AUTOSAR XML (schema 00050)
standard types defined: Boolean
package /ARRoot
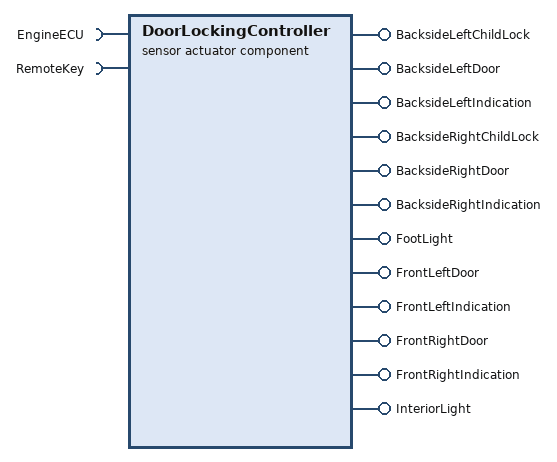
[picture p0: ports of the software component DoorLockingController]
  sensor actuator sw component type DoorLockingController
    6 x provide port:
      BacksideLeftChildLock
      BacksideLeftDoor
      BacksideLeftIndication
      BacksideRightChildLock
      BacksideRightDoor
      BacksideRightIndication
    require port EngineECU
    6 x provide port:
      FootLight
      FrontLeftDoor
      FrontLeftIndication
      FrontRightDoor
      FrontRightIndication
      InteriorLight
    require port RemoteKey
    swc-internal-behavior:
      15 x runnable:
        BacksideLeftChildLockRunnable
        BacksideLeftDoorRunnable
        BacksideLeftIndicationRunnable
        BacksideRightChildLockRunnable
        BacksideRightDoorRunnable
        BacksideRightDoorRunnable
        BacksideRightIndicationRunnable
        EngineECURunnable
        FootLightRunnable
        FrontLeftDoorRunnable
        FrontLeftIndicationRunnable
        FrontRightIndicationRunnable
        IndicationRunnable
        InteriorLightRunnable
        RemoteKeyRunnable
    behavior IndicationIB
    behavior SwitchInputIB
  sender receiver interface DoorLockingSystemSRIF
  sensor actuator sw component type ExteriorLight
